# 3061MNNIKA register map
File version: 1.0
Registers are 32-bit, access per field, reset 0x0 unless marked. A register's access mark holds for its fields unless they carry their own. Offsets are from the block's base; [hi:lo] are bit positions; {n}, {i} and the like mark numbered series.

## SYSCTRL1 — SYSCTRL1_REG peripheral interface
Base 0x10100000
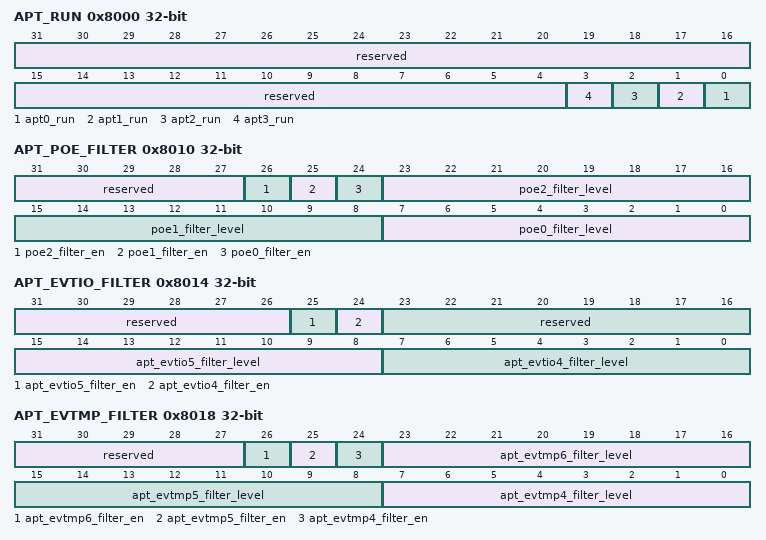
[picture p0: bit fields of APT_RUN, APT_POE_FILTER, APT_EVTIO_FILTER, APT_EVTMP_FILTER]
0x8000 APT_RUN — APT使能控制寄存器。
  [31:4] reserved ro — 保留。
  [n] apt{n}_run rw (n=0..3) — APT{n}使能。 0：不使能； 1：使能。
0x8010 APT_POE_FILTER — APT POE滤波控制寄存器。
  [31:27] reserved ro — 保留。
  [26] poe2_filter_en rw — POE2 FILTER使能。 0：不使能； 1：使能。
  [25] poe1_filter_en rw — POE1 FILTER使能。 0：不使能； 1：使能。
  [24] poe0_filter_en rw — POE0 FILTER使能。 0：不使能； 1：使能。
  [23:16] poe2_filter_level rw — POE2 FILTER周期数（系统总线时钟）。
  [15:8] poe1_filter_level rw — POE1 FILTER周期数（系统总线时钟）。
  [7:0] poe0_filter_level rw — POE0 FILTER周期数（系统总线时钟）。
0x8014 APT_EVTIO_FILTER — APT EVTIO滤波控制寄存器。
  [31:26] reserved ro — 保留。
  [25] apt_evtio5_filter_en rw — APT EVTIO5 FILTER使能。 0：不使能； 1：使能。
  [24] apt_evtio4_filter_en rw — APT EVTIO4 FILTER使能。 0：不使能； 1：使能。
  [23:16] reserved ro — 保留。
  [15:8] apt_evtio5_filter_level rw — APT EVTIO5 FILTER周期数（系统总线时钟）。
  [7:0] apt_evtio4_filter_level rw — APT EVTIO4 FILTER周期数（系统总线时钟）。
0x8018 APT_EVTMP_FILTER — APT EVTMP滤波控制寄存器。
  [31:27] reserved ro — 保留。
  [26] apt_evtmp6_filter_en rw — APT EVTMP6 FILTER使能。 0：不使能； 1：使能。
  [25] apt_evtmp5_filter_en rw — APT EVTMP5 FILTER使能。 0：不使能； 1：使能。
  [24] apt_evtmp4_filter_en rw — APT EVTMP4 FILTER使能。 0：不使能； 1：使能。
  [23:16] apt_evtmp6_filter_level rw — APT EVTMP6 FILTER周期数（系统总线时钟）。
  [15:8] apt_evtmp5_filter_level rw — APT EVTMP5 FILTER周期数（系统总线时钟）。
  [7:0] apt_evtmp4_filter_level rw — APT EVTMP4 FILTER周期数（系统总线时钟）。
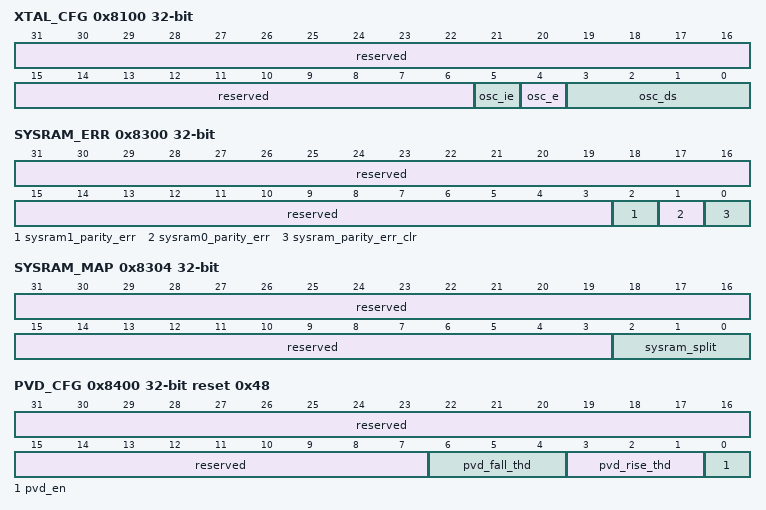
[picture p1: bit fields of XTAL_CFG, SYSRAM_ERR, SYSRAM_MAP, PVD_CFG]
0x8100 XTAL_CFG — 晶体IO控制寄存器。
  [31:6] reserved ro — 保留。
  [5] osc_ie rw — 晶体IO时钟输入使能。 0：不使能； 1：使能。
  [4] osc_e rw — 晶体IO谐振buf使能。 0：不使能； 1：使能。
  [3:0] osc_ds rw — 晶体IO驱动能力配置。 配置值越大，驱动能力越大。
0x8300 SYSRAM_ERR ro — SYSRAM奇偶校验状态寄存器。
  [31:3] reserved — 保留。
  [2] sysram1_parity_err — SYSRAM奇偶校验错误状态。 0：无错误； 1：有错误。
  [1] sysram0_parity_err — SYSRAM奇偶校验错误状态。 0：无错误； 1：有错误。
  [0] sysram_parity_err_clr — SYSRAM奇偶校验错误状态清除。 向该位域执行写动作，会清除SYSRAM奇偶校验错误状态。
0x8304 SYSRAM_MAP — SYSRAM空间分配寄存器。
  [31:3] reserved ro — 保留。
  [2:0] sysram_split rw — SYSRAM空间分配。 000：SYSRAM0 16KB，SYSRAM1 16KB； 001：SYSRAM0 4KB，SYSRAM1 28KB； 010：SYSRAM0 8KB，SYSRAM1 24KB； 011：SYSRAM0 12KB，SYSRAM1 20KB； 100：SYSRAM0 16KB，SYSRAM1 16KB； 101：SYSRAM0 20KB，SYSRAM1 12KB； 110：SYSRAM0 24KB，SYSRAM1 8KB； 111：SYSRAM0 28KB，SYSRAM1 4KB。
0x8400 PVD_CFG reset 0x48 — PVD配置寄存器。
  [31:7] reserved ro — 保留。
  [6:4] pvd_fall_thd rw — PVD下降沿阈值。 000：2.08V； 001：2.18V； 010：2.78V； 011：2.38V； 100：2.48V； 101：2.58V； 110：2.68V； 111：2.78V。
  [3:1] pvd_rise_thd rw — PVD上升沿阈值。 000：2.18V； 001：2.28V； 010：2.38V； 011：2.48V； 100：2.58V； 101：2.68V； 110：2.78V； 111：2.88V。
  [0] pvd_en rw — PVD使能标识。 0：PVD关闭； 1：PVD使能。
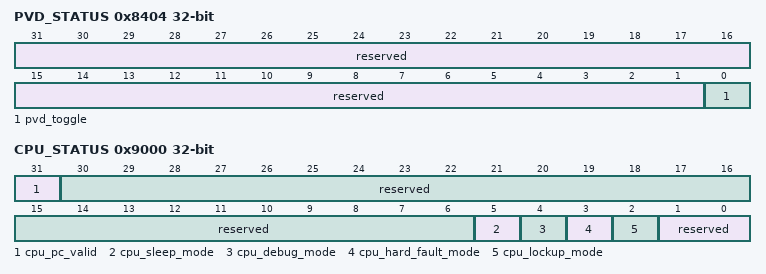
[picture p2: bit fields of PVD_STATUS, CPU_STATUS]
0x8404 PVD_STATUS ro — PVD状态寄存器。
  [31:1] reserved — 保留。
  [0] pvd_toggle — PVD触发标识。
0x9000 CPU_STATUS ro — CPU状态寄存器。
  [31] cpu_pc_valid — CPU PC值有效状态。 0：PC值无效； 1：PC值有效。
  [30:6] reserved — 保留。
  [5] cpu_sleep_mode — CPU SLEEP状态。 0：非sleep状态； 1：sleep状态。
  [4] cpu_debug_mode — CPU DEBUG状态。 0：非debug状态； 1：debug状态。
  [3] cpu_hard_fault_mode — CPU HARD FAULT状态。 0：非hard_fault状态； 1：hard_fault状态。
  [2] cpu_lockup_mode — CPU LOCKUP状态。 0：非lockup状态； 1：lockup状态。
  [1:0] reserved — 保留。

## TIMER0 — TIMER peripheral interface
Base 0x14300000
Same registers: TIMER1 0x14301000, TIMER2 0x14302000, TIMER3 0x14303000
0x00 TIMERx_LOAD rw — 计数初值寄存器
  [31:0] timerload — TIMER的计数初值
0x04 TIMERx_VALUE ro reset 0xFFFFFFFF — 当前计数值寄存器
  [31:0] timervalue — TIMERx当前计数值
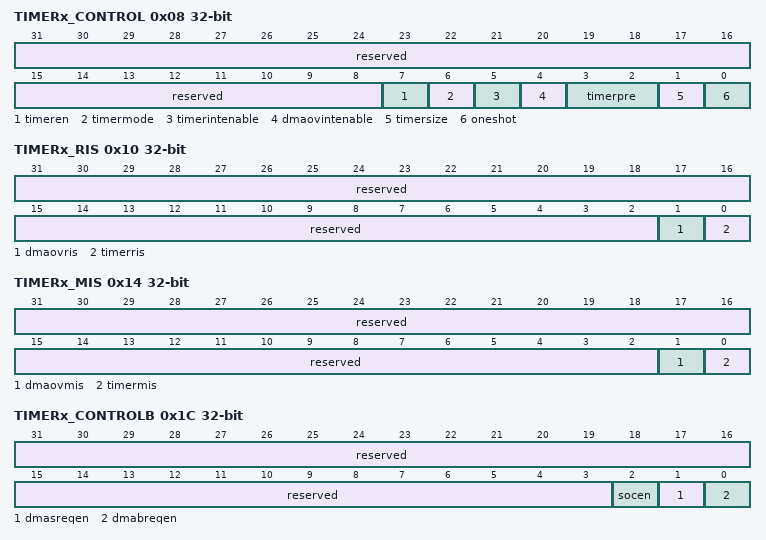
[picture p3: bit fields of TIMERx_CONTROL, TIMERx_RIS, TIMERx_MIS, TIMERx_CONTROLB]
0x08 TIMERx_CONTROL — 控制寄存器
  [31:8] reserved ro — 保留。
  [7] timeren rw — 定时器使能。 0：TIMER禁止； 1：TIMER使能。
  [6] timermode rw — 定时器的计数模式。 0：自由运行模式； 1：周期模式。
  [5] timerintenable rw — 定时中断屏蔽。 0：屏蔽该中断； 1：不屏蔽该中断。
  [4] dmaovintenable rw — DMA请求溢出中断屏蔽。 0：屏蔽该中断； 1：不屏蔽该中断。
  [3:2] timerpre rw — 该字段用于设置TIMER的预分频系数。 00：对clk_timer进行1倍预分频； 01：对clk_timer进行16倍预分频； 10：对clk_timer进行256倍预分频； 11：对clk_timer进行256倍预分频。
  [1] timersize rw — 选择16bit/32bit计数器操作模式。 0：16bit计数器； 1：32bit计数器。
  [0] oneshot rw — 选择计数模式为单次计数模式还是周期计数模式。 0：周期计数模式或自由运行模式； 1：单次计数模式。
0x0C TIMERx_INTCLR wo — 定时中断清除寄存器
  [31:0] timerintclr — 写该寄存器，清除TIMERx的中断输出。
0x10 TIMERx_RIS ro — 原始中断寄存器
  [31:2] reserved — 保留。写入无效，读时返回0。
  [1] dmaovris — DMA请求溢出中断的原始中断状态。 0：未产生中断； 1：已产生中断。
  [0] timerris — 定时中断的原始中断状态。 0：未产生中断； 1：已产生中断。
0x14 TIMERx_MIS ro — 屏蔽后中断寄存器
  [31:2] reserved — 保留。
  [1] dmaovmis — 屏蔽后的DMA请求溢出中断状态。 0：中断无效； 1：中断有效。
  [0] timermis — 屏蔽后的定时中断状态。 0：中断无效； 1：中断有效。
0x18 TIMERx_BGLOAD rw — 计数周期值寄存器
  [31:0] timerbgload — TIMERx的计数周期值。
0x1C TIMERx_CONTROLB — 控制寄存器B
  [31:3] reserved ro — 保留。
  [2] socen rw — 触发ADC采样信号（SOC信号）使能位。 0：计数器计到0时禁止产生SOC信号； 1：计数器计到0时可以产生SOC信号。
  [1] dmasreqen rw — DMA Single请求使能位。 0：计数器计到0时禁止产生DMA Single请求； 1：计数器计到0时可以产生DMA Single请求。
  [0] dmabreqen rw — DMA Burst 请求使能位。 0：计数器计到0时禁止产生DMA Burst请求； 1：计数器计到0时可以产生DMA Burst请求。
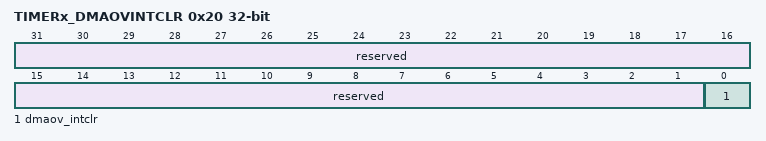
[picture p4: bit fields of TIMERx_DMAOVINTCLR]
0x20 TIMERx_DMAOVINTCLR — DMA请求溢出中断清除寄存器
  [31:1] reserved ro — 保留。
  [0] dmaov_intclr wo — DMA请求溢出中断清除位。 0：写0无效； 1：写1清零。

## TSENSOR — TSENSOR peripheral interface
Base 0x18500000
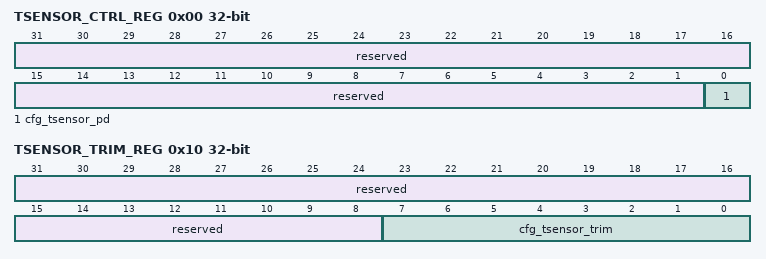
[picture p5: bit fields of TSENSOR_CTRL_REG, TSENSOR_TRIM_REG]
0x00 TSENSOR_CTRL_REG — TSENSOR控制寄存器。
  [31:1] reserved ro — 保留。
  [0] cfg_tsensor_pd rw — Tsensor的关断信号： 0:使能tsensor; 1:关断tsensor。
0x10 TSENSOR_TRIM_REG — TSENSOR TRIM寄存器。
  [31:8] reserved ro — 保留。
  [7:0] cfg_tsensor_trim rw — Tsensor trim信息；

## VREF — VREF peripheral interface
Base 0x18100000
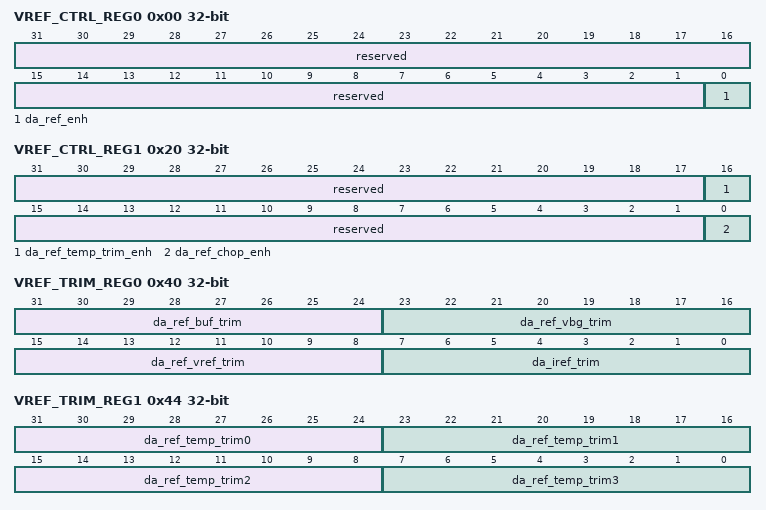
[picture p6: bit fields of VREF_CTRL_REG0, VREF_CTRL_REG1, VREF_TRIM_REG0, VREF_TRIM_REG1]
0x00 VREF_CTRL_REG0 — VREF控制寄存器0。
  [31:1] reserved ro — 保留。
  [0] da_ref_enh rw — VREF模块使能： 0:关闭; 1:使能。
0x20 VREF_CTRL_REG1 — VREF控制寄存器1。
  [31:17] reserved ro — 保留。
  [16] da_ref_temp_trim_enh rw — VREF高精度模式使能： 0:关闭; 1:使能。
  [15:1] reserved ro — 保留。
  [0] da_ref_chop_enh rw — VREF斩波功能使能： 0:关闭; 1:使能。
0x40 VREF_TRIM_REG0 rw — VREF TRIM寄存器0。
  [31:24] da_ref_buf_trim — Vref_buffer trim信息。
  [23:16] da_ref_vbg_trim — VREF电压的trim信息；
  [15:8] da_ref_vref_trim — IBIAS电压的trim信息；
  [7:0] da_iref_trim — Tsensor trim信息；
0x44 VREF_TRIM_REG1 rw — VREF TRIM寄存器1。
  [31-8n:24-8n] da_ref_temp_trim{n} (n=0..3) — 基准温漂trim信息；

## WWDG — WWDG peripheral interface
Base 0x14400000
0x00 WWDG_LOAD 16-bit rw reset 0xFFFF — 计数初值寄存器。
  [15:0] wwdg_load — 计数初值。
0x04 WWDG_VALUE 16-bit ro reset 0xFFFF — 计数器当前值寄存器。
  [15:0] wwdg_value — WatchDog计数器当前值。
0x08 WWDG_WINDOW 16-bit rw reset 0xFFFF — 窗口值寄存器。
  [15:0] wwdg_window — 窗口值，禁止大于计数初值寄存器，否则会产生预期之外的动作。
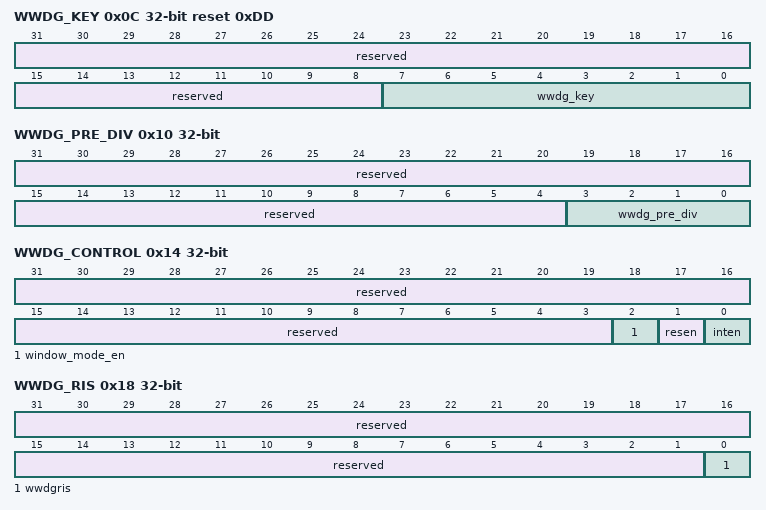
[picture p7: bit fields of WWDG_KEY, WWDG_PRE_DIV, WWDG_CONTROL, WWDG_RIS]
0x0C WWDG_KEY reset 0xDD — 指令字寄存器。
  [31:8] reserved ro — 保留。
  [7:0] wwdg_key rw — 对该寄存器写入0xAA使WatchDog从寄存器WWDG_LOAD中重新载入初值计数（喂狗），并可清除WatchDog的中断。 向该寄存器写入0x55，可打开所有可写寄存器的写权限； 向该寄存器写入其他值，关闭所有可写寄存器写权限；本寄存器始终写有效； 向该寄存器写入0xCC，可开启WWDG； 向该寄存器写入0xDD，可关闭WWDG。
0x10 WWDG_PRE_DIV — 预分频寄存器。
  [31:4] reserved ro — 保留。
  [3:0] wwdg_pre_div rw — 工作时钟的2的幂次分频。 0x0：不分频； 0x1：2分频； 0x2：4分频： …… 0xD：8192分频； 其他：保留。 最多支持8192分频。 配置大于最大分频值的值，按最大分频值进行分频。
0x14 WWDG_CONTROL — 控制寄存器。
  [31:3] reserved ro — 保留。
  [2] window_mode_en rw — WatchDog窗口模式使能。 0：禁止； 1：使能。 当禁止窗口模式时，无需设置wwdg_window，中断固定在wwdg_load/2处产生，此时在任意时刻喂狗均不会触发复位信号，复位信号只有在计数值为0且未清除中断时才会产生。 当使能窗口模式时，wwdg_window值生效，中断在计数器值等于窗口值时产生，在窗口值之外喂狗会产生复位信号，在计数为0且未清除中断时也会产生复位信号。
  [1] resen rw — WatchDog复位信号输出使能。 0：禁止； 1：使能。
  [0] inten rw — WatchDog中断信号输出使能。 0：禁止wwdgmis产生； 1：使能wwdgmis。
0x18 WWDG_RIS ro — 原始中断标志寄存器。
  [31:1] reserved — 保留。
  [0] wwdgris — WatchDog原始中断状态。 0：未产生中断； 1：已产生中断。
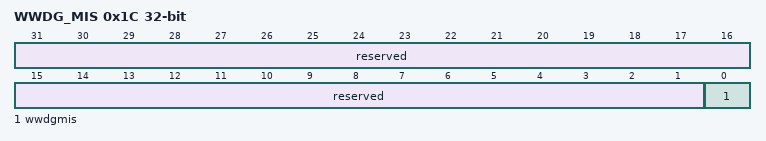
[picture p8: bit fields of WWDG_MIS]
0x1C WWDG_MIS ro — 屏蔽后中断标志寄存器。
  [31:1] reserved — 保留。
  [0] wwdgmis — WatchDog屏蔽后的中断状态。 0：未产生中断或者中断被屏蔽； 1：已产生中断。
